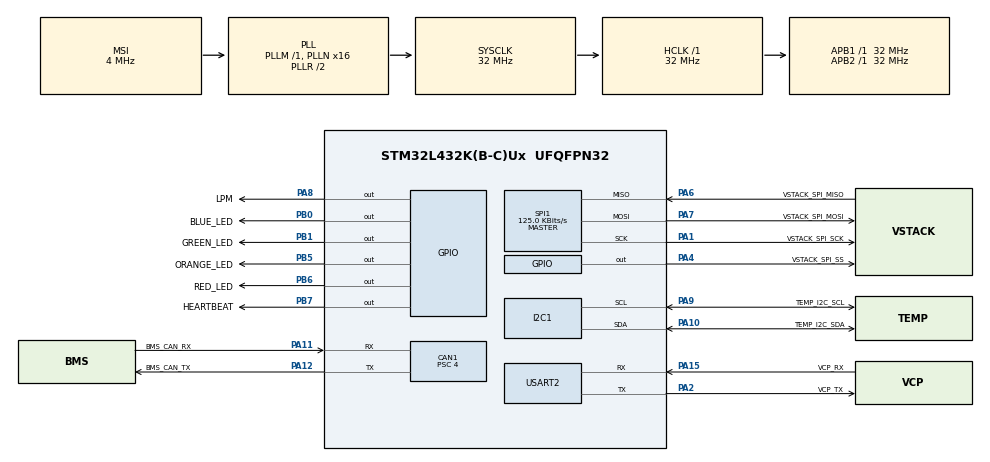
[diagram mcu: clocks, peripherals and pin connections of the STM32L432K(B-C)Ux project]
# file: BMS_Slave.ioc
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CAN1.ABOM=ENABLE
CAN1.AWUM=ENABLE
CAN1.BS1=CAN_BS1_9TQ
CAN1.BS2=CAN_BS2_6TQ
CAN1.CalculateTimeQuantum=125.0
CAN1.Prescaler=4
FREERTOS.INCLUDE_vTaskDelayUntil=1
FREERTOS.Tasks01=defaultTask,0,128,StartDefaultTask,Default,NULL
FREERTOS.configTOTAL_HEAP_SIZE=8000
I2C1.Timing=0x00707CBB
Mcu.Family=STM32L4
Mcu.Name=STM32L432K(B-C)Ux
Mcu.Package=UFQFPN32
NVIC.CAN1_RX0_IRQn=true\:5\:0\:false\:false\:true\:true\:true\:true
NVIC.CAN1_RX1_IRQn=true\:5\:0\:false\:false\:true\:true\:true\:true
NVIC.PriorityGroup=NVIC_PRIORITYGROUP_4
NVIC.SPI1_IRQn=true\:5\:0\:false\:false\:true\:true\:true\:true
NVIC.TIM1_UP_TIM16_IRQn=true\:0\:0\:false\:false\:true\:false\:false\:true
NVIC.TimeBase=TIM1_UP_TIM16_IRQn
NVIC.TimeBaseIP=TIM1
PA0.GPIO_Label=MCO
PA0.Mode=HSE-External-Clock-Source-for-LittleOrca
PA0.Signal=RCC_CK_IN
PA1.GPIO_Label=VSTACK_SPI_SCK
PA1.Mode=Full_Duplex_Master
PA1.Signal=SPI1_SCK
PA10.GPIO_Label=TEMP_I2C_SDA
PA10.Mode=I2C
PA10.Signal=I2C1_SDA
PA11.GPIO_Label=BMS_CAN_RX
PA11.Mode=Master
PA11.Signal=CAN1_RX
PA12.GPIO_Label=BMS_CAN_TX
PA12.Mode=Master
PA12.Signal=CAN1_TX
PA13\ (JTMS-SWDIO).Mode=Serial_Wire
PA13\ (JTMS-SWDIO).Signal=SYS_JTMS-SWDIO
PA14\ (JTCK-SWCLK).Mode=Serial_Wire
PA14\ (JTCK-SWCLK).Signal=SYS_JTCK-SWCLK
PA15\ (JTDI).GPIO_Label=VCP_RX
PA15\ (JTDI).Mode=Asynchronous
PA15\ (JTDI).Signal=USART2_RX
PA2.GPIO_Label=VCP_TX
PA2.Mode=Asynchronous
PA2.Signal=USART2_TX
PA4.GPIO_Label=VSTACK_SPI_SS
PA4.Signal=GPIO_Output
PA6.GPIO_Label=VSTACK_SPI_MISO
PA6.Mode=Full_Duplex_Master
PA6.Signal=SPI1_MISO
PA7.GPIO_Label=VSTACK_SPI_MOSI
PA7.Mode=Full_Duplex_Master
PA7.Signal=SPI1_MOSI
PA8.GPIO_Label=LPM
PA8.Signal=GPIO_Output
PA9.GPIO_Label=TEMP_I2C_SCL
PA9.Mode=I2C
PA9.Signal=I2C1_SCL
PB0.GPIO_Label=BLUE_LED
PB0.Signal=GPIO_Output
PB1.GPIO_Label=GREEN_LED
PB1.Signal=GPIO_Output
PB5.GPIO_Label=ORANGE_LED
PB5.Signal=GPIO_Output
PB6.GPIO_Label=RED_LED
PB6.Signal=GPIO_Output
PB7.GPIO_Label=HEARTBEAT
PB7.Signal=GPIO_Output
PC14-OSC32_IN\ (PC14).Mode=LSE-External-Oscillator
PC14-OSC32_IN\ (PC14).Signal=RCC_OSC32_IN
PC15-OSC32_OUT\ (PC15).Mode=LSE-External-Oscillator
PC15-OSC32_OUT\ (PC15).Signal=RCC_OSC32_OUT
ProjectManager.HeapSize=0x200
ProjectManager.StackSize=0x400
ProjectManager.TargetToolchain=SW4STM32
RCC.AHBFreq_Value=32000000
RCC.APB1Freq_Value=32000000
RCC.APB1TimFreq_Value=32000000
RCC.APB2Freq_Value=32000000
RCC.APB2TimFreq_Value=32000000
RCC.CortexFreq_Value=32000000
RCC.HCLKFreq_Value=32000000
RCC.HSE_VALUE=8000000
RCC.HSI48_VALUE=48000000
RCC.HSI_VALUE=16000000
RCC.MSIAutoCalibration=ENABLED
RCC.MSI_VALUE=4000000
RCC.PLLN=16
RCC.SYSCLKFreq_VALUE=32000000
RCC.SYSCLKSource=RCC_SYSCLKSOURCE_PLLCLK
RCC.VCOOutputFreq_Value=64000000
SPI1.BaudRatePrescaler=SPI_BAUDRATEPRESCALER_256
SPI1.CLKPhase=SPI_PHASE_2EDGE
SPI1.CLKPolarity=SPI_POLARITY_HIGH
SPI1.CalculateBaudRate=125.0 KBits/s
SPI1.DataSize=SPI_DATASIZE_8BIT
SPI1.Direction=SPI_DIRECTION_2LINES
SPI1.Mode=SPI_MODE_MASTER
SPI1.VirtualType=VM_MASTER
USART2.VirtualMode-Asynchronous=VM_ASYNC
VP_FREERTOS_VS_CMSIS_V1.Mode=CMSIS_V1
VP_SYS_VS_tim1.Mode=TIM1
board=custom

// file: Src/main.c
/* USER CODE BEGIN Header */
/**
  ******************************************************************************
  * @file           : main.c
  * @brief          : Main program body
  ******************************************************************************
  * This notice applies to any and all portions of this file
  * that are not between comment pairs USER CODE BEGIN and
  * USER CODE END. Other portions of this file, whether
  * inserted by the user or by software development tools
  * are owned by their respective copyright owners.
  *
  * Copyright (c) 2019 STMicroelectronics International N.V.
  * All rights reserved.
  *
  * Redistribution and use in source and binary forms, with or without
  * modification, are permitted, provided that the following conditions are met:
  *
  * 1. Redistribution of source code must retain the above copyright notice,
  *    this list of conditions and the following disclaimer.
  * 2. Redistributions in binary form must reproduce the above copyright notice,
  *    this list of conditions and the following disclaimer in the documentation
  *    and/or other materials provided with the distribution.
  * 3. Neither the name of STMicroelectronics nor the names of other
  *    contributors to this software may be used to endorse or promote products
  *    derived from this software without specific written permission.
  * 4. This software, including modifications and/or derivative works of this
  *    software, must execute solely and exclusively on microcontroller or
  *    microprocessor devices manufactured by or for STMicroelectronics.
  * 5. Redistribution and use of this software other than as permitted under
  *    this license is void and will automatically terminate your rights under
  *    this license.
  *
  * THIS SOFTWARE IS PROVIDED BY STMICROELECTRONICS AND CONTRIBUTORS "AS IS"
  * AND ANY EXPRESS, IMPLIED OR STATUTORY WARRANTIES, INCLUDING, BUT NOT
  * LIMITED TO, THE IMPLIED WARRANTIES OF MERCHANTABILITY, FITNESS FOR A
  * PARTICULAR PURPOSE AND NON-INFRINGEMENT OF THIRD PARTY INTELLECTUAL PROPERTY
  * RIGHTS ARE DISCLAIMED TO THE FULLEST EXTENT PERMITTED BY LAW. IN NO EVENT
  * SHALL STMICROELECTRONICS OR CONTRIBUTORS BE LIABLE FOR ANY DIRECT, INDIRECT,
  * INCIDENTAL, SPECIAL, EXEMPLARY, OR CONSEQUENTIAL DAMAGES (INCLUDING, BUT NOT
  * LIMITED TO, PROCUREMENT OF SUBSTITUTE GOODS OR SERVICES; LOSS OF USE, DATA,
  * OR PROFITS; OR BUSINESS INTERRUPTION) HOWEVER CAUSED AND ON ANY THEORY OF
  * LIABILITY, WHETHER IN CONTRACT, STRICT LIABILITY, OR TORT (INCLUDING
  * NEGLIGENCE OR OTHERWISE) ARISING IN ANY WAY OUT OF THE USE OF THIS SOFTWARE,
  * EVEN IF ADVISED OF THE POSSIBILITY OF SUCH DAMAGE.
  *
  ******************************************************************************
  */
/* USER CODE END Header */

#include "main.h"
#include "cmsis_os.h"

/* USER CODE BEGIN Includes */
#include "bms.h"
#include "stm32l4xx_hal_uart.h"
/* USER CODE END Includes */

CAN_HandleTypeDef hcan1;

I2C_HandleTypeDef hi2c1;

SPI_HandleTypeDef hspi1;

UART_HandleTypeDef huart2;

osThreadId defaultTaskHandle;

void SystemClock_Config(void);
static void MX_GPIO_Init(void);
static void MX_CAN1_Init(void);
static void MX_SPI1_Init(void);
static void MX_I2C1_Init(void);
static void MX_USART2_UART_Init(void);
void StartDefaultTask(void const * argument);

int main(void)
{

  /* MCU Configuration--------------------------------------------------------*/

  /* Reset of all peripherals, Initializes the Flash interface and the Systick. */
  HAL_Init();

  /* Configure the system clock */
  SystemClock_Config();

  /* Initialize all configured peripherals */
  MX_GPIO_Init();
  MX_CAN1_Init();
  MX_SPI1_Init();
  MX_I2C1_Init();
  MX_USART2_UART_Init();
  /* USER CODE BEGIN 2 */
  //can_filter_init(&hcan1);
  //HAL_CAN_Start(&hcan1);

  //HAL_CAN_ActivateNotification(&hcan1, CAN_IT_RX_FIFO0_MSG_PENDING);

#if (TRACE_ENABLE == 1)
  vTraceEnable(TRC_START);
#endif

  initRTOSObjects();
  initBMSobject(ASSERTED);
  /* USER CODE END 2 */

  /* Create the thread(s) */
  /* definition and creation of defaultTask */
  osThreadDef(defaultTask, StartDefaultTask, osPriorityNormal, 0, 128);
  defaultTaskHandle = osThreadCreate(osThread(defaultTask), NULL);

  /* Start scheduler */
  osKernelStart();

  /* We should never get here as control is now taken by the scheduler */

  /* Infinite loop */
  while (1) {

  }
}

void SystemClock_Config(void)
{
  RCC_OscInitTypeDef RCC_OscInitStruct = {0};
  RCC_ClkInitTypeDef RCC_ClkInitStruct = {0};
  RCC_PeriphCLKInitTypeDef PeriphClkInit = {0};

  /** Configure LSE Drive Capability
  */
  HAL_PWR_EnableBkUpAccess();
  __HAL_RCC_LSEDRIVE_CONFIG(RCC_LSEDRIVE_LOW);
  /** Initializes the CPU, AHB and APB busses clocks
  */
  RCC_OscInitStruct.OscillatorType = RCC_OSCILLATORTYPE_LSE|RCC_OSCILLATORTYPE_MSI;
  RCC_OscInitStruct.LSEState = RCC_LSE_ON;
  RCC_OscInitStruct.MSIState = RCC_MSI_ON;
  RCC_OscInitStruct.MSICalibrationValue = 0;
  RCC_OscInitStruct.MSIClockRange = RCC_MSIRANGE_6;
  RCC_OscInitStruct.PLL.PLLState = RCC_PLL_ON;
  RCC_OscInitStruct.PLL.PLLSource = RCC_PLLSOURCE_MSI;
  RCC_OscInitStruct.PLL.PLLM = 1;
  RCC_OscInitStruct.PLL.PLLN = 16;
  RCC_OscInitStruct.PLL.PLLP = RCC_PLLP_DIV7;
  RCC_OscInitStruct.PLL.PLLQ = RCC_PLLQ_DIV2;
  RCC_OscInitStruct.PLL.PLLR = RCC_PLLR_DIV2;
  if (HAL_RCC_OscConfig(&RCC_OscInitStruct) != HAL_OK)
  {
    Error_Handler();
  }
  /** Initializes the CPU, AHB and APB busses clocks
  */
  RCC_ClkInitStruct.ClockType = RCC_CLOCKTYPE_HCLK|RCC_CLOCKTYPE_SYSCLK
                              |RCC_CLOCKTYPE_PCLK1|RCC_CLOCKTYPE_PCLK2;
  RCC_ClkInitStruct.SYSCLKSource = RCC_SYSCLKSOURCE_PLLCLK;
  RCC_ClkInitStruct.AHBCLKDivider = RCC_SYSCLK_DIV1;
  RCC_ClkInitStruct.APB1CLKDivider = RCC_HCLK_DIV1;
  RCC_ClkInitStruct.APB2CLKDivider = RCC_HCLK_DIV1;

  if (HAL_RCC_ClockConfig(&RCC_ClkInitStruct, FLASH_LATENCY_1) != HAL_OK)
  {
    Error_Handler();
  }
  PeriphClkInit.PeriphClockSelection = RCC_PERIPHCLK_USART2|RCC_PERIPHCLK_I2C1;
  PeriphClkInit.Usart2ClockSelection = RCC_USART2CLKSOURCE_PCLK1;
  PeriphClkInit.I2c1ClockSelection = RCC_I2C1CLKSOURCE_PCLK1;
  if (HAL_RCCEx_PeriphCLKConfig(&PeriphClkInit) != HAL_OK)
  {
    Error_Handler();
  }
  /** Configure the main internal regulator output voltage
  */
  if (HAL_PWREx_ControlVoltageScaling(PWR_REGULATOR_VOLTAGE_SCALE1) != HAL_OK)
  {
    Error_Handler();
  }
  /** Enable MSI Auto calibration
  */
  HAL_RCCEx_EnableMSIPLLMode();
}

static void MX_CAN1_Init(void)
{

  hcan1.Instance = CAN1;
  hcan1.Init.Prescaler = 4;
  hcan1.Init.Mode = CAN_MODE_NORMAL;
  hcan1.Init.SyncJumpWidth = CAN_SJW_1TQ;
  hcan1.Init.TimeSeg1 = CAN_BS1_9TQ;
  hcan1.Init.TimeSeg2 = CAN_BS2_6TQ;
  hcan1.Init.TimeTriggeredMode = DISABLE;
  hcan1.Init.AutoBusOff = ENABLE;
  hcan1.Init.AutoWakeUp = ENABLE;
  hcan1.Init.AutoRetransmission = DISABLE;
  hcan1.Init.ReceiveFifoLocked = DISABLE;
  hcan1.Init.TransmitFifoPriority = DISABLE;
  if (HAL_CAN_Init(&hcan1) != HAL_OK)
  {
    Error_Handler();
  }

}

static void MX_I2C1_Init(void)
{

  hi2c1.Instance = I2C1;
  hi2c1.Init.Timing = 0x00707CBB;
  hi2c1.Init.OwnAddress1 = 0;
  hi2c1.Init.AddressingMode = I2C_ADDRESSINGMODE_7BIT;
  hi2c1.Init.DualAddressMode = I2C_DUALADDRESS_DISABLE;
  hi2c1.Init.OwnAddress2 = 0;
  hi2c1.Init.OwnAddress2Masks = I2C_OA2_NOMASK;
  hi2c1.Init.GeneralCallMode = I2C_GENERALCALL_DISABLE;
  hi2c1.Init.NoStretchMode = I2C_NOSTRETCH_DISABLE;
  if (HAL_I2C_Init(&hi2c1) != HAL_OK)
  {
    Error_Handler();
  }
  /** Configure Analogue filter
  */
  if (HAL_I2CEx_ConfigAnalogFilter(&hi2c1, I2C_ANALOGFILTER_ENABLE) != HAL_OK)
  {
    Error_Handler();
  }
  /** Configure Digital filter
  */
  if (HAL_I2CEx_ConfigDigitalFilter(&hi2c1, 0) != HAL_OK)
  {
    Error_Handler();
  }

}

static void MX_SPI1_Init(void)
{

  /* SPI1 parameter configuration*/
  hspi1.Instance = SPI1;
  hspi1.Init.Mode = SPI_MODE_MASTER;
  hspi1.Init.Direction = SPI_DIRECTION_2LINES;
  hspi1.Init.DataSize = SPI_DATASIZE_8BIT;
  hspi1.Init.CLKPolarity = SPI_POLARITY_HIGH;
  hspi1.Init.CLKPhase = SPI_PHASE_2EDGE;
  hspi1.Init.NSS = SPI_NSS_SOFT;
  hspi1.Init.BaudRatePrescaler = SPI_BAUDRATEPRESCALER_256;
  hspi1.Init.FirstBit = SPI_FIRSTBIT_MSB;
  hspi1.Init.TIMode = SPI_TIMODE_DISABLE;
  hspi1.Init.CRCCalculation = SPI_CRCCALCULATION_DISABLE;
  hspi1.Init.CRCPolynomial = 7;
  hspi1.Init.CRCLength = SPI_CRC_LENGTH_DATASIZE;
  hspi1.Init.NSSPMode = SPI_NSS_PULSE_DISABLE;
  if (HAL_SPI_Init(&hspi1) != HAL_OK)
  {
    Error_Handler();
  }

}

static void MX_USART2_UART_Init(void)
{

  huart2.Instance = USART2;
  huart2.Init.BaudRate = 115200;
  huart2.Init.WordLength = UART_WORDLENGTH_8B;
  huart2.Init.StopBits = UART_STOPBITS_1;
  huart2.Init.Parity = UART_PARITY_NONE;
  huart2.Init.Mode = UART_MODE_TX_RX;
  huart2.Init.HwFlowCtl = UART_HWCONTROL_NONE;
  huart2.Init.OverSampling = UART_OVERSAMPLING_16;
  huart2.Init.OneBitSampling = UART_ONE_BIT_SAMPLE_DISABLE;
  huart2.AdvancedInit.AdvFeatureInit = UART_ADVFEATURE_NO_INIT;
  if (HAL_UART_Init(&huart2) != HAL_OK)
  {
    Error_Handler();
  }

}

static void MX_GPIO_Init(void)
{
  GPIO_InitTypeDef GPIO_InitStruct = {0};

  /* GPIO Ports Clock Enable */
  __HAL_RCC_GPIOC_CLK_ENABLE();
  __HAL_RCC_GPIOA_CLK_ENABLE();
  __HAL_RCC_GPIOB_CLK_ENABLE();

  /*Configure GPIO pin Output Level */
  HAL_GPIO_WritePin(GPIOA, VSTACK_SPI_SS_Pin|LPM_Pin, GPIO_PIN_RESET);

  /*Configure GPIO pin Output Level */
  HAL_GPIO_WritePin(GPIOB, BLUE_LED_Pin|GREEN_LED_Pin|ORANGE_LED_Pin|RED_LED_Pin
                          |HEARTBEAT_Pin, GPIO_PIN_RESET);

  /*Configure GPIO pins : VSTACK_SPI_SS_Pin LPM_Pin */
  GPIO_InitStruct.Pin = VSTACK_SPI_SS_Pin|LPM_Pin;
  GPIO_InitStruct.Mode = GPIO_MODE_OUTPUT_PP;
  GPIO_InitStruct.Pull = GPIO_NOPULL;
  GPIO_InitStruct.Speed = GPIO_SPEED_FREQ_LOW;
  HAL_GPIO_Init(GPIOA, &GPIO_InitStruct);

  /*Configure GPIO pins : BLUE_LED_Pin GREEN_LED_Pin ORANGE_LED_Pin RED_LED_Pin
                           HEARTBEAT_Pin */
  GPIO_InitStruct.Pin = BLUE_LED_Pin|GREEN_LED_Pin|ORANGE_LED_Pin|RED_LED_Pin
                          |HEARTBEAT_Pin;
  GPIO_InitStruct.Mode = GPIO_MODE_OUTPUT_PP;
  GPIO_InitStruct.Pull = GPIO_NOPULL;
  GPIO_InitStruct.Speed = GPIO_SPEED_FREQ_LOW;
  HAL_GPIO_Init(GPIOB, &GPIO_InitStruct);

}

void StartDefaultTask(void const * argument)
{

  for(;;)
  {
    osDelay(1);
  }
}

void HAL_TIM_PeriodElapsedCallback(TIM_HandleTypeDef *htim)
{
  if (htim->Instance == TIM1) {
    HAL_IncTick();
  }
}

void Error_Handler(void)
{
}

/************************ (C) COPYRIGHT STMicroelectronics *****END OF FILE****/

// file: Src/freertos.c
/* USER CODE BEGIN Header */
/**
  ******************************************************************************
  * File Name          : freertos.c
  * Description        : Code for freertos applications
  ******************************************************************************
  * This notice applies to any and all portions of this file
  * that are not between comment pairs USER CODE BEGIN and
  * USER CODE END. Other portions of this file, whether
  * inserted by the user or by software development tools
  * are owned by their respective copyright owners.
  *
  * Copyright (c) 2019 STMicroelectronics International N.V.
  * All rights reserved.
  *
  * Redistribution and use in source and binary forms, with or without
  * modification, are permitted, provided that the following conditions are met:
  *
  * 1. Redistribution of source code must retain the above copyright notice,
  *    this list of conditions and the following disclaimer.
  * 2. Redistributions in binary form must reproduce the above copyright notice,
  *    this list of conditions and the following disclaimer in the documentation
  *    and/or other materials provided with the distribution.
  * 3. Neither the name of STMicroelectronics nor the names of other
  *    contributors to this software may be used to endorse or promote products
  *    derived from this software without specific written permission.
  * 4. This software, including modifications and/or derivative works of this
  *    software, must execute solely and exclusively on microcontroller or
  *    microprocessor devices manufactured by or for STMicroelectronics.
  * 5. Redistribution and use of this software other than as permitted under
  *    this license is void and will automatically terminate your rights under
  *    this license.
  *
  * THIS SOFTWARE IS PROVIDED BY STMICROELECTRONICS AND CONTRIBUTORS "AS IS"
  * AND ANY EXPRESS, IMPLIED OR STATUTORY WARRANTIES, INCLUDING, BUT NOT
  * LIMITED TO, THE IMPLIED WARRANTIES OF MERCHANTABILITY, FITNESS FOR A
  * PARTICULAR PURPOSE AND NON-INFRINGEMENT OF THIRD PARTY INTELLECTUAL PROPERTY
  * RIGHTS ARE DISCLAIMED TO THE FULLEST EXTENT PERMITTED BY LAW. IN NO EVENT
  * SHALL STMICROELECTRONICS OR CONTRIBUTORS BE LIABLE FOR ANY DIRECT, INDIRECT,
  * INCIDENTAL, SPECIAL, EXEMPLARY, OR CONSEQUENTIAL DAMAGES (INCLUDING, BUT NOT
  * LIMITED TO, PROCUREMENT OF SUBSTITUTE GOODS OR SERVICES; LOSS OF USE, DATA,
  * OR PROFITS; OR BUSINESS INTERRUPTION) HOWEVER CAUSED AND ON ANY THEORY OF
  * LIABILITY, WHETHER IN CONTRACT, STRICT LIABILITY, OR TORT (INCLUDING
  * NEGLIGENCE OR OTHERWISE) ARISING IN ANY WAY OUT OF THE USE OF THIS SOFTWARE,
  * EVEN IF ADVISED OF THE POSSIBILITY OF SUCH DAMAGE.
  *
  ******************************************************************************
  */
/* USER CODE END Header */

#include "FreeRTOS.h"
#include "task.h"
#include "main.h"

/* Pre/Post sleep processing prototypes */
void PreSleepProcessing(uint32_t *ulExpectedIdleTime);
void PostSleepProcessing(uint32_t *ulExpectedIdleTime);

/* Hook prototypes */
void configureTimerForRunTimeStats(void);
unsigned long getRunTimeCounterValue(void);

/* USER CODE BEGIN 1 */
/* Functions needed when configGENERATE_RUN_TIME_STATS is on */
__weak void configureTimerForRunTimeStats(void)
{

}

__weak unsigned long getRunTimeCounterValue(void)
{
return 0;
}
/* USER CODE END 1 */

/* USER CODE BEGIN PREPOSTSLEEP */
__weak void PreSleepProcessing(uint32_t *ulExpectedIdleTime)
{
/* place for user code */
}

__weak void PostSleepProcessing(uint32_t *ulExpectedIdleTime)
{
/* place for user code */
}
/* USER CODE END PREPOSTSLEEP */

/************************ (C) COPYRIGHT STMicroelectronics *****END OF FILE****/
